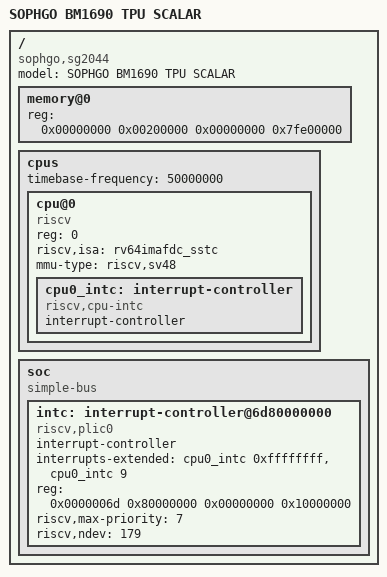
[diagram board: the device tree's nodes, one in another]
// SPDX-License-Identifier: (GPL-2.0 OR MIT)
/*
 * Copyright (C) 2022 Sophgo Technology Inc. All rights reserved.
 */

/ {
	model = "SOPHGO BM1690 TPU SCALAR";
	compatible = "sophgo,sg2044";
	#address-cells = <2>;
	#size-cells = <2>;

	memory@0 {
		device_type = "memory";
		reg = <0x00000000 0x00200000 0x00000000 0x7fe00000>;
	};

	cpus {
		#address-cells = <1>;
		#size-cells = <0>;
		timebase-frequency = <50000000>;
		cpu@0 {
			device_type = "cpu";
			reg = <0>;
			status = "okay";
			compatible = "riscv";
			riscv,isa = "rv64imafdc_sstc";
			mmu-type = "riscv,sv48";
			cpu0_intc: interrupt-controller {
				#interrupt-cells = <1>;
				compatible = "riscv,cpu-intc";
				interrupt-controller;
			};
		};
	};

	soc {
		#address-cells = <2>;
		#size-cells = <2>;
		compatible = "simple-bus";
		ranges;

		//1cores PLIC1
		intc: interrupt-controller@6d80000000 {
			#interrupt-cells = <1>;
			compatible = "riscv,plic0";
			interrupt-controller;
			interrupts-extended = <
				&cpu0_intc  0xffffffff &cpu0_intc  9
				>;
			reg = <0x0000006d 0x80000000 0x00000000 0x10000000>;
			reg-names = "control";
			riscv,max-priority = <7>;
			riscv,ndev = <179>;
		};
	};
};
